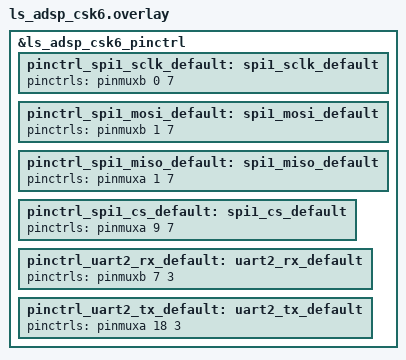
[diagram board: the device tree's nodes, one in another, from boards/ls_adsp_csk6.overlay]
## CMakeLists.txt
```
cmake_minimum_required(VERSION 3.20.0)

# SPDX-License-Identifier: Apache-2.0
#

if("${BOARD}" STREQUAL "ls_adsp_csk6")
set(ENV{XCC_USE_CLANG} "1")
set(ENV{ZEPHYR_TOOLCHAIN_VARIANT} "xcc")
endif()

if("${BOARD}" STREQUAL "ls_adsp_csk6")
	message(INFO " ${BOARD} compiles as remote in this sample")
else()
	message(FATAL_ERROR "${BOARD} was not supported for this sample")
endif()

find_package(Zephyr REQUIRED HINTS $ENV{ZEPHYR_BASE})
project(csk6_ai)

target_sources(app PRIVATE src/main.c)
target_include_directories(app PRIVATE ${CMAKE_CURRENT_SOURCE_DIR}/..)

add_subdirectory(./src)
target_include_directories(app PRIVATE ${CMAKE_CURRENT_SOURCE_DIR} ./src) 

set(LIB_DIR  ${CMAKE_CURRENT_SOURCE_DIR}/lib)
message(INFO " ${CMAKE_CURRENT_SOURCE_DIR} ABC")

target_include_directories(app PUBLIC ${CMAKE_CURRENT_SOURCE_DIR}/include/)
target_include_directories(app PUBLIC ${CMAKE_CURRENT_SOURCE_DIR}/include/cjson/)
target_include_directories(app PUBLIC ${CMAKE_CURRENT_SOURCE_DIR}/include/opi_cpy/)
target_include_directories(app PUBLIC ${CMAKE_CURRENT_SOURCE_DIR}/include/luna/)
target_include_directories(app PUBLIC ${CMAKE_CURRENT_SOURCE_DIR}/include/istitch/)
target_include_directories(app PUBLIC ${CMAKE_CURRENT_SOURCE_DIR}/include/cutline/)
target_include_directories(app PUBLIC ${CMAKE_CURRENT_SOURCE_DIR}/include/ocr/)
target_include_directories(app PUBLIC ${CMAKE_CURRENT_SOURCE_DIR}/include/trans/)
target_include_directories(app PUBLIC ${CMAKE_CURRENT_SOURCE_DIR}/include/tts/)

target_link_libraries(app PUBLIC -Wl,--start-group 
						 -lgcc 
						 -lc 
						 -lm 
						 -lgloss 
						 -lminrt 
						 ${LIB_DIR}/libopi_cpy.a 
						 ${LIB_DIR}/libluna.a 
						 ${LIB_DIR}/libistitch.a 
						 ${LIB_DIR}/libls_cutline.a 
						 ${LIB_DIR}/libls_ocr.a 
						 ${LIB_DIR}/libls_trans.a 
						 ${LIB_DIR}/libhifi_dsp.a 
						 ${LIB_DIR}/libcjson.a 
						 ${LIB_DIR}/libls_trans.a 
						 ${LIB_DIR}/libthinker.a 
						 ${LIB_DIR}/libtts.a 
						 -Wl,--end-group)
```

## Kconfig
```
config SOF_AI_CV
	bool "Sof camera image ai"
	default n
	help
	  Select for Sof camera image ai support.
	  This will cause cv to include camera image ai library.

config SOF_AI_CUTLINE_RES_ADDR
	hex "Sof cutline algorithm resource address"
	default 0x68800000
	depends on SOF_AI_CV
	help
	  Sof cutline algorithm resource address.
	
config SOF_AI_CUTLINE_RES_SIZE
	hex "Sof cutline algorithm resource size"
	default 430632
	depends on SOF_AI_CV
	help
	  Sof cutline algorithm resource size.

config SOF_AI_OCR_RES_ADDR
	hex "Sof ocr algorithm resource address"
	default 0x68880000
	depends on SOF_AI_CV
	help
	  Sof ocr algorithm resource address.

config SOF_AI_OCR_RES_SIZE
	hex "Sof ocr algorithm resource size"
	default 2523608
	depends on SOF_AI_CV
	help
	  Sof ocr algorithm resource size.

config SOF_AI_TTS_RES_ADDR
	hex "Sof tts algorithm resource address"
	default 0x68b00000
	depends on SOF_AI_CV
	help
	  Sof tts algorithm resource address.

config SOF_AI_TTS_RES_SIZE
	hex "Sof tts algorithm resource size"
	default 0
	depends on SOF_AI_CV
	help
	  Sof tts algorithm resource size.

config SOF_AI_TRANS_RES_ADDR
	hex "Sof translate algorithm resource address"
	default 0x68f80000
	depends on SOF_AI_CV
	help
	  Sof translate algorithm resource address.

config SOF_AI_TRANS_RES_SIZE
	hex "Sof translate algorithm resource size"
	default 0
	depends on SOF_AI_CV
	help
	  Sof translate algorithm resource size.

source "Kconfig.zephyr"
```

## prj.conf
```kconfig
CONFIG_PRINTK=y
CONFIG_CBPRINTF_FP_SUPPORT=y
CONFIG_STDOUT_CONSOLE=n
CONFIG_EXTERNAL_LIBC=y

# CONFIG_DMA=y
CONFIG_HEAP_MEM_POOL_SIZE=409600
CONFIG_MAIN_STACK_SIZE=81920
CONFIG_BUILD_OUTPUT_BIN=y

# CONFIG_XTENSA_ENABLE_BACKTRACE=y

# CONFIG_THREAD_ANALYZER=y
# CONFIG_THREAD_ANALYZER_USE_PRINTK=y
# CONFIG_THREAD_ANALYZER_AUTO=y
# CONFIG_THREAD_ANALYZER_AUTO_INTERVAL=5
# CONFIG_THREAD_RUNTIME_STATS=y
# CONFIG_THREAD_NAME=y

# ai
CONFIG_SOF_AI_CV=y
CONFIG_XTENSA_ENABLE_BACKTRACE=y
# CONFIG_TIMER_READS_ITS_FREQUENCY_AT_RUNTIME=y
```

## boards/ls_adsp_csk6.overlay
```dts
&ls_adsp_csk6_pinctrl{

		pinctrl_spi1_sclk_default: spi1_sclk_default {
            pinctrls = < &pinmuxb 0 7 >;
		};

		pinctrl_spi1_mosi_default: spi1_mosi_default {
            pinctrls = < &pinmuxb 1 7 >;
		};

		pinctrl_spi1_miso_default: spi1_miso_default {
            pinctrls = < &pinmuxa 1 7 >;
		};

        pinctrl_spi1_cs_default: spi1_cs_default {
            pinctrls = < &pinmuxa 9 7 >;
		};

        pinctrl_uart2_rx_default: uart2_rx_default {
			pinctrls = < &pinmuxb 7 3 >;
		};

		pinctrl_uart2_tx_default: uart2_tx_default {
			pinctrls = < &pinmuxa 18 3 >;
		};

};
```

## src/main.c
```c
/*
 *
 * SPDX-License-Identifier: Apache-2.0
 */

#include <zephyr.h>
#include <sys/printk.h>

#include <string.h>

#include "venus_cp.h"
#include "luna/luna.h"
#include "hal/ClockManager.h"

#include "dma_venus.h"

#include "cv.h"
#include "img.h"

#define BMP_128_180_HEAD_LEN (14 + 40 + 1024)
#define BMP_128_180_DATA_LEN (128*180)
#define BMP_128_180_LEN (BMP_128_180_HEAD_LEN + BMP_128_180_DATA_LEN)

#define BMP_IMG_WIDTH (128)
static __attribute__((aligned(4))) uint8_t temp_buf[280 * BMP_IMG_WIDTH] = {0};

static void
csk_dma_irq_handler(const struct device *dev)
{
    dma_irq_handler();
}

void main(void)
{
    uint8_t *src = NULL;
    uint8_t *dest = NULL;
    int src_len = 0;
    int dest_len = 0;    

    printk("[Remote][%s %d] Enter...\n",__FUNCTION__,__LINE__);

    /* dma initialize */
	IRQ_CONNECT(3, 1, csk_dma_irq_handler, NULL, 0);                                                                                                          
	irq_enable(3);
    dma_initialize();

    /* get test input bmp information */
    int image_cnt = sizeof(img_resource) / (BMP_128_180_LEN);
    printk("image cnt: %d\n", image_cnt);

    /* xy crop prepare */
    ai_xy_crop_new();
    ai_xy_crop_prepare();

    /* cutline ocr prepare */
    ai_cutline_ocr_prepare();

    printk("[0]: ai prepare done\n");

    for(int i = 0; i < image_cnt; i++){
        /* 1. find x,y offset 
         * 2. output cropped frame */
        src = (uint8_t *)img_resource  + i * BMP_128_180_LEN + BMP_128_180_HEAD_LEN;
        src_len = BMP_128_180_DATA_LEN;
        dest = (uint8_t *)temp_buf;
        ai_xy_crop_copy(src, src_len, dest, &dest_len);

        /* 1. collect cuted frame 
         * 2. if stop scanning then use cutline algothrim
         * 3. use ocr algothrim to get result */
        src = dest;
        src_len = dest_len;
        dest = NULL;
        dest_len = 0;
        ai_cutline_ocr_copy(src, src_len);
    }

    dest = (uint8_t *)temp_buf;
    dest_len = 0;
    ai_cutline_ocr_deal(&dest, &dest_len);

    ai_cutline_ocr_free();

E2D:
	while(1){
		k_msleep(100);
	}
}
```
